# M0519AE_v1 register map
File version: 1.0
Registers are 32-bit, read-write, reset 0x0 unless marked. A register's access mark holds for its fields unless they carry their own. Offsets are from the block's base; [hi:lo] are bit positions.

## WDT — WDT Register Map
Base 0x40004000
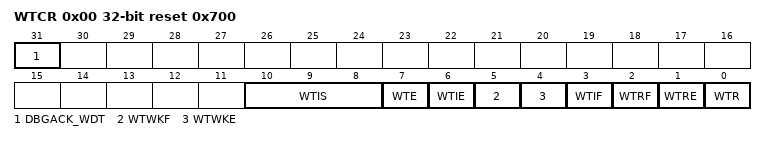
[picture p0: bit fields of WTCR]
0x00 WTCR reset 0x700 — WDT Control Register
  [31] DBGACK_WDT — ICE Debug Mode Acknowledge Disable (Write Protect). WDT up counter will keep going no matter CPU is held by ICE or not. Note: This bit is write protected. Refer to the REGWRPROT register.
    0=ICE debug mode acknowledgement affects WDT counting; 1=ICE debug mode acknowledgement Disabled
  [10:8] WTIS — WDT Time-out Interval Selection (Write Protect). These three bits select the time-out interval period for the WDT. Note: This bit is write protected. Refer to the REGWRPROT register.
    0=24 * WDT_CLK; 1=26 * WDT_CLK; 2=28 * WDT_CLK; 3=210 * WDT_CLK; 4=212 * WDT_CLK; 5=214 * WDT_CLK; 6=216 * WDT_CLK; 7=218 * WDT_CLK
  [7] WTE — WDT Enable Bit (Write Protect). Note1: This bit is write protected. Refer to the REGWRPROT register. Note2: If CWDTEN (Config0[31]) bits is configure to 0, this bit is forced as 1 and user cannot change this bit to 0.
    0=WDT Disabled (This action will reset the internal up counter value); 1=WDT Enabled
  [6] WTIE — WDT Time-out Interrupt Enable Bit (Write Protect). If this bit is enabled, the WDT time-out interrupt signal is generated and inform to CPU. Note: This bit is write protected. Refer to the REGWRPROT register.
    0=WDT time-out interrupt Disabled; 1=WDT time-out interrupt Enabled
  [5] WTWKF — WDT Time-out Wake-up Flag (Write Protect). This bit indicates the interrupt wake-up flag status of WDT. Note1: This bit is write protected. Refer to the REGWRPROT register. Note2: This bit is cleared by writing 1 to it.
    0=WDT does not cause chip wake-up; 1=Chip wake-up from Idle or Power-down mode if WDT time-out interrupt signal generated
  [4] WTWKE — WDT Time-out Wake-up Function Control (Write Protect). If this bit is set to 1, while WDT time-out interrupt flag IF (WTCR[3]) is generated to 1 and interrupt enable bit WTIE (WTCR[6]) is enabled, the WDT time-out interrupt signal will generate a wake-up trigger event to chip. Note1: This bit is write protected. Refer to the REGWRPROT register. Note2: Chip can be woken-up by WDT time-out interrupt signal generated only if WDT clock source is selected to 10 kHz internal low speed RC oscillator (LIRC).
    0=Wake-up trigger event Disabled if WDT time-out interrupt signal generated; 1=Wake-up trigger event Enabled if WDT time-out interrupt signal generated
  [3] WTIF — WDT Time-out Interrupt Flag. This bit will set to 1 while WDT up counter value reaches the selected WDT time-out interval. Note: This bit is cleared by writing 1 to it.
    0=WDT time-out interrupt did not occur; 1=WDT time-out interrupt occurred
  [2] WTRF — WDT Time-out Reset Flag. This bit indicates the system has been reset by WDT time-out reset or not. Note: This bit is cleared by writing 1 to it.
    0=WDT time-out reset did not occur; 1=WDT time-out reset occurred
  [1] WTRE — WDT Time-out Reset Enable Bit (Write Protect). Setting this bit will enable the WDT time-out reset function If the WDT up counter value has not been cleared after the specific WDT reset delay period expires. Note: This bit is write protected. Refer to the REGWRPROT register.
    0=WDT time-out reset function Disabled; 1=WDT time-out reset function Enabled
  [0] WTR — Reset WDT Up Counter (Write Protect). Note1: This bit is write protected. Refer to the REGWRPROT register. Note2: This bit will be automatically cleared by hardware.
    0=No effect; 1=Reset the internal 18-bit WDT up counter value
0x04 WTCRALT — WDT Alternative Control Register
  [1:0] WTRDSEL — WDT Reset Delay Selection (Write Protect). When WDT time-out happened, user has a time named WDT Reset Delay Period to clear WDT counter by setting WTR (WTCR[0]) to prevent WDT time-out reset happened. User can select a suitable setting of WTRDSEL for different WDT Reset Delay Period. Note1: This bit is write protected. Refer to the REGWRPROT register. Note2: This register will be reset to 0 if WDT time-out reset happened.
    0=WDT Reset Delay Period is 1026 * WDT_CLK; 1=WDT Reset Delay Period is 130 * WDT_CLK; 2=WDT Reset Delay Period is 18 * WDT_CLK; 3=WDT Reset Delay Period is 3 * WDT_CLK
